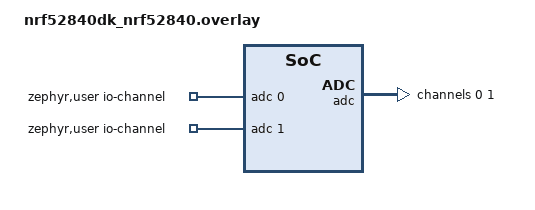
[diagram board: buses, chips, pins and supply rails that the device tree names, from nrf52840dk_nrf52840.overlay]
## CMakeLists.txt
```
#
# Copyright (c) 2020 Nordic Semiconductor ASA
#
# SPDX-License-Identifier: LicenseRef-Nordic-5-Clause
#
cmake_minimum_required(VERSION 3.20.0)

find_package(Zephyr REQUIRED HINTS $ENV{ZEPHYR_BASE})
project(NONE)

# NORDIC SDK APP START
target_sources(app PRIVATE
	src/main.c
	src/model_handler.c
	src/radiator_cli.c)
target_include_directories(app PRIVATE include)

# NORDIC SDK APP END
```

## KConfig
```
# /Kconfig
# this is all you need!
source "Kconfig.zephyr"

menu "Radiator Sensor"

config SENSOR_NUMBER
	int "The sensor's number"
	range 0 255
	default 0

endmenu
```

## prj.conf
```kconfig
#
# Copyright (c) 2020 Nordic Semiconductor ASA
#
# SPDX-License-Identifier: LicenseRef-Nordic-5-Clause
#
# Deffered logging helps improve LPN power consumption
# when friendship is established.

# ADC
CONFIG_NEWLIB_LIBC=y
CONFIG_ADC=y
CONFIG_PM_DEVICE=y

# Logging
CONFIG_LOG_MODE_DEFERRED=y
CONFIG_LOG=y
CONFIG_LOG_BACKEND_RTT=y
CONFIG_RTT_CONSOLE=y

# General configuration
CONFIG_FLASH=y
CONFIG_FLASH_MAP=y
CONFIG_NVS=y
CONFIG_SETTINGS=y
CONFIG_HWINFO=y
CONFIG_DK_LIBRARY=y
CONFIG_PM_SINGLE_IMAGE=y
CONFIG_PM_PARTITION_SIZE_SETTINGS_STORAGE=0x8000
CONFIG_SOC_FLASH_NRF_PARTIAL_ERASE=y

# Bluetooth configuration
CONFIG_BT=y
CONFIG_BT_COMPANY_ID=0x0059
CONFIG_BT_DEVICE_NAME="Radiator Sensor"
CONFIG_BT_L2CAP_TX_BUF_COUNT=8
CONFIG_BT_OBSERVER=y
CONFIG_BT_PERIPHERAL=y
CONFIG_BT_SETTINGS=y
CONFIG_BT_RX_STACK_SIZE=2150

# Disable unused Bluetooth features
CONFIG_BT_CTLR_DUP_FILTER_LEN=0
CONFIG_BT_CTLR_LE_ENC=n
CONFIG_BT_DATA_LEN_UPDATE=n
CONFIG_BT_PHY_UPDATE=n
CONFIG_BT_CTLR_CHAN_SEL_2=n
CONFIG_BT_CTLR_MIN_USED_CHAN=n
CONFIG_BT_CTLR_PRIVACY=n

# Bluetooth mesh configuration
CONFIG_BT_MESH=y
CONFIG_BT_MESH_RELAY=y
CONFIG_BT_MESH_FRIEND=y
CONFIG_BT_MESH_ADV_BUF_COUNT=13
CONFIG_BT_MESH_TX_SEG_MAX=10
CONFIG_BT_MESH_PB_GATT=y
CONFIG_BT_MESH_GATT_PROXY=y
CONFIG_BT_MESH_PROXY_USE_DEVICE_NAME=y
CONFIG_BT_MESH_DK_PROV=y
CONFIG_BT_MESH_CFG_CLI=y
CONFIG_BT_MESH_DEFAULT_TTL=3
CONFIG_NEWLIB_LIBC_MIN_REQUIRED_HEAP_SIZE=2048
CONFIG_SENSOR_NUMBER=6
```

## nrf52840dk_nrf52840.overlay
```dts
/*
 * SPDX-License-Identifier: Apache-2.0
 *
 * Copyright (c) 2022 Nordic Semiconductor ASA
 */

 / {
	zephyr,user {
		io-channels = <&adc 0>, <&adc 1>;
	};
};

&adc {
	#address-cells = <1>;
	#size-cells = <0>;

	channel@0 {
		reg = <0>;
		zephyr,gain = "ADC_GAIN_1_5";
		zephyr,reference = "ADC_REF_INTERNAL";
		zephyr,acquisition-time = <ADC_ACQ_TIME_DEFAULT>;
		zephyr,input-positive = <NRF_SAADC_AIN1>; 
		zephyr,resolution = <12>;
        zephyr,oversampling = <8>;
	};

	channel@1 {
		reg = <1>;
		zephyr,gain = "ADC_GAIN_1_5";
		zephyr,reference = "ADC_REF_INTERNAL";
		zephyr,acquisition-time = <ADC_ACQ_TIME_DEFAULT>;
		zephyr,input-positive = <NRF_SAADC_AIN2>;
		zephyr,resolution = <12>;
		zephyr,oversampling = <8>;
	};
};
```

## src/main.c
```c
#include <zephyr/bluetooth/bluetooth.h>
#include <zephyr/bluetooth/mesh.h>
#include <bluetooth/mesh/models.h>
#include <bluetooth/mesh/dk_prov.h>

#include <math.h>

#include <zephyr/device.h>
#include <zephyr/devicetree.h>
#include <zephyr/drivers/adc.h>

#include <zephyr/drivers/gpio.h>

#include <dk_buttons_and_leds.h>

#include <zephyr/pm/pm.h>
#include <zephyr/pm/device.h>
#include <zephyr/pm/policy.h>

#include "radiator_cli.h"
#include "model_handler.h"

static const uint16_t net_idx;
static const uint16_t app_idx;
static const uint32_t iv_index;
static uint8_t flags;

#define THERMISTORNOMINAL 10000
#define TEMPERATURENOMINAL 25
#define BCOEFFICIENT 3977
#define SERIESRESISTOR 10000

#if !DT_NODE_EXISTS(DT_PATH(zephyr_user)) || \
	!DT_NODE_HAS_PROP(DT_PATH(zephyr_user), io_channels)
#error "No suitable devicetree overlay specified"
#endif

#define DT_SPEC_AND_COMMA(node_id, prop, idx) \
	ADC_DT_SPEC_GET_BY_IDX(node_id, idx),

/* Data of ADC io-channels specified in devicetree. */
static const struct adc_dt_spec adc_channels[] = {
	DT_FOREACH_PROP_ELEM(DT_PATH(zephyr_user), io_channels, DT_SPEC_AND_COMMA)
};

static void bt_ready(int err)
{
	if (err) {
		printk("Bluetooth init failed (err %d)\n", err);
		return;
	}

	printk("Bluetooth initialized\n");

	dk_leds_init();

	// ****
	// * This is the standard code that enables provisioning.
	// * For testing, fix the network and app keys
	// ***
	
	// err = bt_mesh_init(bt_mesh_dk_prov_init(), model_handler_init());
	// if (err) {
	// 	printk("Initializing mesh failed (err %d)\n", err);
	// 	return;
	// }

	// if (IS_ENABLED(CONFIG_SETTINGS)) {
	// 	settings_load();
	// }

	// /* This will be a no-op if settings_load() loaded provisioning info */
	//bt_mesh_prov_enable(BT_MESH_PROV_ADV | BT_MESH_PROV_GATT);

	static const uint8_t dev_uuid[16] = { 0xdd, 0xdd };

	static const struct bt_mesh_prov prov = {
		.uuid = dev_uuid
	};

	err = bt_mesh_init(&prov, model_handler_init());
	if (err) {
		printk("Initializing mesh failed (err %d)\n", err);
		return;
	}

	settings_load();

	static const uint8_t net_key[16] = {
		0x01, 0x23, 0x45, 0x67, 0x89, 0xab, 0xcd, 0xef,
		0x01, 0x23, 0x45, 0x67, 0x89, 0xab, 0xcd, 0xef,
	};

	static const uint8_t dev_key[16] = {
		0x01, 0x23, 0x45, 0x67, 0x89, 0xab, 0xcd, 0xef,
		0x01, 0x23, 0x45, 0x67, 0x89, 0xab, 0xcd, 0xef,
	};

	static const uint8_t app_key[16] = {
		0x01, 0x23, 0x45, 0x67, 0x89, 0xab, 0xcd, 0xef,
		0x01, 0x23, 0x45, 0x67, 0x89, 0xab, 0xcd, 0xef,
	};

	int config_number = CONFIG_SENSOR_NUMBER;

	uint16_t addr = config_number;

	err = bt_mesh_provision(net_key, net_idx, flags, iv_index, addr, dev_key);
	
	if (err == -EALREADY) {
		printk("Using stored settings\n");
	} else if (err) {
		printk("Provisioning failed (err %d)\n", err);
		return;
	} else {
		printk("Provisioning completed\n");
	
		// Bind the AppKey
		//
		bt_mesh_cfg_cli_app_key_add(net_idx, addr, net_idx, app_idx, app_key, NULL);

		// Bind the Radiator model to the key
		//
		bt_mesh_cfg_cli_mod_app_bind_vnd(net_idx, addr, addr, app_idx, BT_MESH_RADIATOR_CLI_VENDOR_MODEL_ID, BT_COMP_ID_LF, NULL);
	}

	printk("Mesh initialized\n");
}

int16_t buf;

struct adc_sequence sequence = {
	.buffer = &buf,
	.buffer_size = sizeof(buf),
	.calibrate = true,
};

uint16_t read(int i)
{
	int err = adc_sequence_init_dt(&adc_channels[i], &sequence);

	if (err < 0)
	{
		printk("Could initialise ADC (%d)\n", err);
		return -1;
	}
	
	err = adc_read(adc_channels[i].dev, &sequence);

	if (err < 0)
	{
		printk("Could not read (%d)\n", err);
		return -1;
	}

	int32_t val_mv = buf;

	float reading = (4096.0 / val_mv) - 1; // (4096/ADC - 1)

	reading = SERIESRESISTOR / reading;

	float steinhart;
	steinhart = reading / THERMISTORNOMINAL;		  // (R/Ro)
	steinhart = log(steinhart);						  // ln(R/Ro)
	steinhart /= BCOEFFICIENT;						  // 1/B * ln(R/Ro)
	steinhart += 1.0 / (TEMPERATURENOMINAL + 273.15); // + (1/To)
	steinhart = 1.0 / steinhart;					  // Invert
	steinhart -= 273.15;							  // Convert to Celcius	

	uint16_t value = (uint16_t)(steinhart * 10);

	return value;
}

void main(void)
{
	int err;

	printk("Initializing...\n");

	const struct device *const cons = DEVICE_DT_GET(DT_CHOSEN(zephyr_console));
	
	for (size_t i = 0U; i < ARRAY_SIZE(adc_channels); i++)
	{
		if (!device_is_ready(adc_channels[i].dev))
		{
			printk("ADC controller device not ready\n");
			return;
		}

		err = adc_channel_setup_dt(&adc_channels[i]);

		if (err < 0)
		{
			printk("Could not setup channel #%d (%d)\n", i, err);
			return;
		}

		printk("Setup channel #%d (%d)\n", i, err);
	}

	err = bt_enable(bt_ready);
	if (err) {
		printk("Bluetooth init failed (err %d)\n", err);
	}

	for(;;) {
		
		uint16_t flow_temperature = read(0);
		uint16_t return_temperature = read(1);

		cmd_send_reading(flow_temperature, return_temperature);

		k_sleep(K_SECONDS(5));
	}
}
```

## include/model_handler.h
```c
/*
 * Copyright (c) 2020 Nordic Semiconductor ASA
 *
 * SPDX-License-Identifier: LicenseRef-Nordic-5-Clause
 */

/**
 * @file
 * @brief Model handler
 */

#ifndef MODEL_HANDLER_H__
#define MODEL_HANDLER_H__

#include <zephyr/bluetooth/mesh.h>

#ifdef __cplusplus
extern "C" {
#endif

const struct bt_mesh_comp *model_handler_init(void);

void cmd_send_reading(uint16_t flow_temperature, uint16_t return_temperature);

#ifdef __cplusplus
}
#endif

#endif /* MODEL_HANDLER_H__ */
```

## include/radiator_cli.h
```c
#ifndef BT_MESH_RADIATOR_CLI_H__
#define BT_MESH_RADIATOR_CLI_H__

#include <zephyr/bluetooth/mesh.h>
#include <bluetooth/mesh/model_types.h>

#define BT_MESH_RADIATOR_CLI_VENDOR_COMPANY_ID    0x0059
#define BT_MESH_RADIATOR_CLI_VENDOR_MODEL_ID      0x000A

#define BT_MESH_RADIATOR_CLI_OP_READING_SET BT_MESH_MODEL_OP_3(0x0A, BT_MESH_RADIATOR_CLI_VENDOR_COMPANY_ID)
#define BT_MESH_RADIATOR_CLI_OP_READING_LENGTH 9

struct bt_mesh_radiator_cli;

#define BT_MESH_MODEL_RADIATOR_CLI(_radiators)                               \
		BT_MESH_MODEL_VND_CB(BT_MESH_RADIATOR_CLI_VENDOR_COMPANY_ID,         \
			BT_MESH_RADIATOR_CLI_VENDOR_MODEL_ID,                            \
			_bt_mesh_radiator_cli_op, &(_radiators)->pub,                    \
			BT_MESH_MODEL_USER_DATA(struct bt_mesh_radiator_cli, _radiators),\
			&_bt_mesh_radiator_cli_cb)

struct bt_mesh_radiator_cli {
	struct bt_mesh_model *model;
	struct bt_mesh_model_pub pub;
	struct net_buf_simple pub_msg;
	uint8_t buf[BT_MESH_MODEL_BUF_LEN(BT_MESH_RADIATOR_CLI_OP_READING_SET, BT_MESH_RADIATOR_CLI_OP_READING_LENGTH)];
	const struct bt_mesh_radiator_cli_handlers *handlers;
};

struct bt_mesh_radiator_cli_handlers {
    void (*const reading)(struct bt_mesh_radiator_cli *chat,
			              struct bt_mesh_msg_ctx *ctx,
			              const uint8_t *msg);
};

int bt_mesh_radiator_cli_reading_set(struct bt_mesh_radiator_cli *radiator, uint16_t flow_temperature, uint16_t return_temperature);

extern const struct bt_mesh_model_op _bt_mesh_radiator_cli_op[];
extern const struct bt_mesh_model_cb _bt_mesh_radiator_cli_cb;

#endif
```

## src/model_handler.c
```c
/*
 * Copyright (c) 2020 Nordic Semiconductor ASA
 *
 * SPDX-License-Identifier: LicenseRef-Nordic-5-Clause
 */

#include <zephyr/device.h>
#include <zephyr/devicetree.h>
#include <zephyr/bluetooth/bluetooth.h>
#include <bluetooth/mesh/models.h>
#include <bluetooth/mesh/sensor_types.h>
#include <dk_buttons_and_leds.h>
#include "model_handler.h"
#include "radiator_cli.h"

static bool address_is_local(struct bt_mesh_model *mod, uint16_t addr)
{
	return bt_mesh_model_elem(mod)->addr == addr;
}

static void handle_reading(struct bt_mesh_radiator_cli *radiator,
						   struct bt_mesh_msg_ctx *ctx,
						   const uint8_t *msg)
{
	/* Don't print own messages. */
	if (address_is_local(radiator->model, ctx->addr)) {
		return;
	}
}

static const struct bt_mesh_radiator_cli_handlers radiator_handlers = {
	.reading = handle_reading
};

static struct bt_mesh_radiator_cli radiator = {
	.handlers = &radiator_handlers
};

static struct bt_mesh_elem elements[] = {
    BT_MESH_ELEM(
        1,
        BT_MESH_MODEL_LIST(BT_MESH_MODEL_CFG_SRV),
        BT_MESH_MODEL_LIST(BT_MESH_MODEL_RADIATOR_CLI(&radiator))),
};

static const struct bt_mesh_comp comp = {
	.cid = CONFIG_BT_COMPANY_ID,
	.elem = elements,
	.elem_count = ARRAY_SIZE(elements),
};

const struct bt_mesh_comp *model_handler_init(void)
{
	return &comp;
}

void cmd_send_reading(uint16_t flow_temperature, uint16_t return_temperature) 
{
	int err = bt_mesh_radiator_cli_reading_set(&radiator, flow_temperature, return_temperature);

	if(err) {
		printk("Bluetooth radiator set failed (err %d)\n", err);
	}
}
```

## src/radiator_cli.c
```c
#include <zephyr/bluetooth/mesh.h>
#include "radiator_cli.h"
#include "mesh/net.h"
#include <string.h>

#include <zephyr/logging/log.h>
LOG_MODULE_DECLARE(radiator);

static int handle_reading(struct bt_mesh_model *model, struct bt_mesh_msg_ctx *ctx, struct net_buf_simple *buf)
{
	return 0;
}

static int bt_mesh_radiator_cli_update_handler(struct bt_mesh_model *model)
{
	return 0;
}

static int bt_mesh_radiator_cli_init(struct bt_mesh_model *model)
{
    printk("bt_mesh_radiator_cli_init()\n");

	struct bt_mesh_radiator_cli *radiator = model->user_data;

	radiator->model = model;

	net_buf_simple_init_with_data(&radiator->pub_msg, radiator->buf, sizeof(radiator->buf));
	radiator->pub.msg = &radiator->pub_msg;
	radiator->pub.update = bt_mesh_radiator_cli_update_handler;

	return 0;
}

static int bt_mesh_radiator_cli_start(struct bt_mesh_model *model)
{
	return 0;
}

const struct bt_mesh_model_op _bt_mesh_radiator_cli_op[] = {
    { BT_MESH_RADIATOR_CLI_OP_READING_SET, 9, handle_reading },
	BT_MESH_MODEL_OP_END,
};

const struct bt_mesh_model_cb _bt_mesh_radiator_cli_cb = {
    .init = bt_mesh_radiator_cli_init,
	.start = bt_mesh_radiator_cli_start,
};

int bt_mesh_radiator_cli_reading_set(struct bt_mesh_radiator_cli *radiator, uint16_t flow_temperature, uint16_t return_temperature)
{
    printk("bt_mesh_radiator_cli_reading_set()\n");

    struct net_buf_simple *buf = radiator->model->pub->msg;

	bt_mesh_model_msg_init(buf, BT_MESH_RADIATOR_CLI_OP_READING_SET);

	int config_sensor_number = CONFIG_SENSOR_NUMBER;
	uint8_t number = config_sensor_number;

	net_buf_simple_add_u8(buf, number);
	net_buf_simple_add_le16(buf, flow_temperature);
	net_buf_simple_add_le16(buf, return_temperature);

    printk("Length to publish: %d\n", radiator->model->pub->msg->len);

    // Broadcast to everyone!
    //radiator->model->pub->addr = 0xFFFF;

	// Target the Bridge node (number 99)
	radiator->model->pub->addr = 0x0063;
    radiator->model->pub->ttl = 3;
		
    int err = bt_mesh_model_publish(radiator->model);

    if(err) {
        printk("Failed to publish: %d\n", err);
    }

    return err;
}
```
